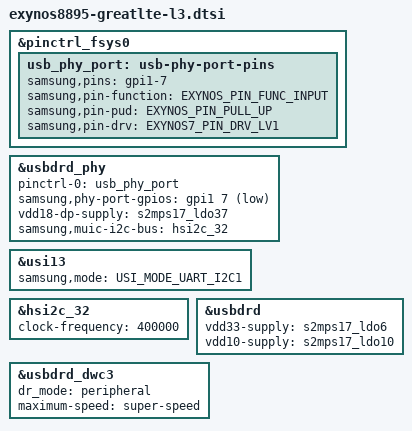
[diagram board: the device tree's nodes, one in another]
// SPDX-License-Identifier: GPL-2.0 OR BSD-3-Clause
/*
 * Samsung Galaxy Note 8 (greatlte, SM-N950N) board DT, part "l3":
 * L3 USB peripheral (L3 4).
 *
 * Included at the end of exynos8895-greatlte.dts, after L0's nodes, in the merge
 * order of FULL_IMAGE_PLAN.md 2.2. Owner: WP-L3; no other work package edits this
 * file (plan 2.3 rule D1). A node that two parts both configure (&usi9, &usi10)
 * is written identically in both files: dtc lets the later file win on a differing
 * value, which gl-verify V-DUP reports as an error. L0's reserved-memory stays in
 * the .dts; carveout additions and flag changes are &label edits here (plan X-8).
 */

#include <dt-bindings/gpio/gpio.h>
#include <dt-bindings/soc/samsung,exynos-usi.h>

/*
 * Type-C orientation input USB3.1_COM_SEL, gpi1-7: input, pull-up, drive LV1 (FDT:741-748;
 * S:arch/arm64/boot/dts/exynos/exynos8895-greatlte_gpio_06.dtsi:39 "PIN_IN(gpi1-7, UP, LV1);",
 * included by exynos8895-greatlte_eur_open_06.dts:19, the hw_rev 6..255 board of the shipped DTB).
 */
&pinctrl_fsys0 {
	usb_phy_port: usb-phy-port-pins {
		samsung,pins = "gpi1-7";
		samsung,pin-function = <EXYNOS_PIN_FUNC_INPUT>;	/* FDT:743 <0x00> */
		samsung,pin-pud = <EXYNOS_PIN_PULL_UP>;		/* FDT:744 <0x03> */
		samsung,pin-drv = <EXYNOS7_PIN_DRV_LV1>;	/* FDT:745 <0x00> */
	};
};

&usbdrd_phy {
	pinctrl-names = "default";				/* FDT:7893-7894 */
	pinctrl-0 = <&usb_phy_port>;
	/*
	 * stock "phy,gpio_phy_port = <&gpi1 7 0>" (FDT:7895) and port = !level
	 * (S:drivers/phy/phy-exynos-usbdrd.c:767-768): active low gives value == port
	 */
	samsung,phy-port-gpios = <&gpi1 7 GPIO_ACTIVE_LOW>;
	vdd18-dp-supply = <&s2mps17_ldo37>;			/* VDD_DP_1P8, FDT:7242-7246 */
	/*
	 * MAX77865 MUIC (0x25) on hsi2c@10970000 (FDT:6149-6166): its CONTROL1 switch must
	 * route D+/D- to the AP (0x89), stock S:drivers/muic/universal/muic_apis.c:235-245
	 */
	samsung,muic-i2c-bus = <&hsi2c_32>;
	status = "okay";
};

/*
 * The MAX77865 bus, only for the MUIC switch write of the PHY (and the L3 heartbeat's MUIC
 * read). Written exactly as spec/L6F_power_input_misc.md 4.3 will (plan D1: identical in
 * both parts).
 */
&usi13 {
	samsung,mode = <USI_MODE_UART_I2C1>;	/* stock usi@1082102C usi_mode = "uart_hsi2c1" FDT:5077-5081 */
	status = "okay";
};

&hsi2c_32 {					/* stock hsi2c@10970000 FDT:6149-6163 (SPI 0x1ab = 427) */
	clock-frequency = <400000>;		/* stock default HSI2C_FS_TX_CLOCK (FDT has none) */
	status = "okay";
};

&usbdrd {
	vdd33-supply = <&s2mps17_ldo6>;				/* vdd_ldo6 3.1 V, FDT:7102-7107, 11239 */
	vdd10-supply = <&s2mps17_ldo10>;			/* vdd_ldo10, FDT:7136-7141, 11240 */
	status = "okay";
};

&usbdrd_dwc3 {
	dr_mode = "peripheral";		/* stock "otg" (FDT:7875); peripheral only in L3 (1.1) */
	maximum-speed = "super-speed";	/* FDT:7876 */
};
